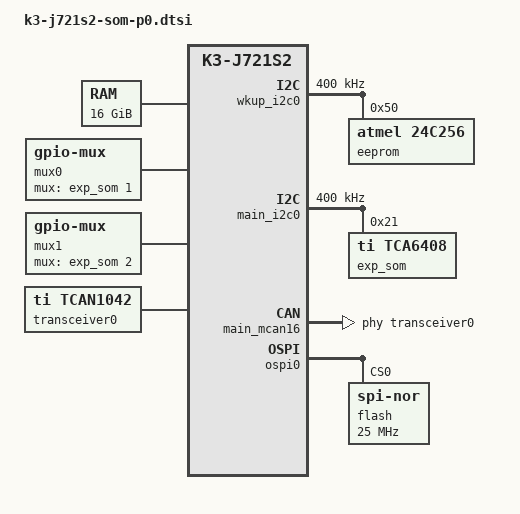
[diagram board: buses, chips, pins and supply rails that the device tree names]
/dts-v1/;
#include "k3-j721s2.dtsi"
#include <dt-bindings/gpio/gpio.h>
/ {
	memory@80000000 {
		device_type = "memory";
		reg = <0x00 0x80000000 0x00 0x80000000>,
		      <0x08 0x80000000 0x03 0x80000000>;
	};
	reserved_memory: reserved-memory {
		#address-cells = <2>;
		#size-cells = <2>;
		ranges;
		secure_ddr: optee@9e800000 {
			reg = <0x00 0x9e800000 0x00 0x01800000>;
			alignment = <0x1000>;
			no-map;
		};
	};
	mux0: mux-controller {
		compatible = "gpio-mux";
		#mux-state-cells = <1>;
		mux-gpios = <&exp_som 1 GPIO_ACTIVE_HIGH>;
	};
	mux1: mux-controller {
		compatible = "gpio-mux";
		#mux-state-cells = <1>;
		mux-gpios = <&exp_som 2 GPIO_ACTIVE_HIGH>;
	};
	transceiver0: can-phy0 {
		compatible = "ti,tcan1042";
		#phy-cells = <0>;
		max-bitrate = <5000000>;
	};
};
&wkup_pmx0 {
	mcu_fss0_ospi0_pins_default: mcu-fss0-ospi0-default-pins {
		pinctrl-single,pins = <
			J721S2_WKUP_IOPAD(0x000, PIN_OUTPUT, 0)  
			J721S2_WKUP_IOPAD(0x02c, PIN_OUTPUT, 0)  
			J721S2_WKUP_IOPAD(0x00c, PIN_INPUT, 0)  
			J721S2_WKUP_IOPAD(0x010, PIN_INPUT, 0)  
			J721S2_WKUP_IOPAD(0x014, PIN_INPUT, 0)  
			J721S2_WKUP_IOPAD(0x018, PIN_INPUT, 0)  
			J721S2_WKUP_IOPAD(0x01c, PIN_INPUT, 0)  
			J721S2_WKUP_IOPAD(0x020, PIN_INPUT, 0)  
			J721S2_WKUP_IOPAD(0x024, PIN_INPUT, 0)  
			J721S2_WKUP_IOPAD(0x028, PIN_INPUT, 0)  
			J721S2_WKUP_IOPAD(0x008, PIN_INPUT, 0)  
			J721S2_WKUP_IOPAD(0x004, PIN_INPUT, 0)  
		>;
	};
};
&wkup_pmx2 {
	wkup_i2c0_pins_default: wkup-i2c0-default-pins {
		pinctrl-single,pins = <
			J721S2_WKUP_IOPAD(0x98, PIN_INPUT, 0)  
			J721S2_WKUP_IOPAD(0x9c, PIN_INPUT, 0)  
		>;
	};
};
&main_pmx0 {
	main_i2c0_pins_default: main-i2c0-default-pins {
		pinctrl-single,pins = <
			J721S2_IOPAD(0x0e0, PIN_INPUT_PULLUP, 0)  
			J721S2_IOPAD(0x0e4, PIN_INPUT_PULLUP, 0)  
		>;
	};
	main_mcan16_pins_default: main-mcan16-default-pins {
		pinctrl-single,pins = <
			J721S2_IOPAD(0x028, PIN_INPUT, 0)  
			J721S2_IOPAD(0x024, PIN_OUTPUT, 0)  
		>;
	};
};
&wkup_i2c0 {
	status = "okay";
	pinctrl-names = "default";
	pinctrl-0 = <&wkup_i2c0_pins_default>;
	clock-frequency = <400000>;
	eeprom@50 {
		compatible = "atmel,24c256";
		reg = <0x50>;
	};
};
&main_i2c0 {
	status = "okay";
	pinctrl-names = "default";
	pinctrl-0 = <&main_i2c0_pins_default>;
	clock-frequency = <400000>;
	exp_som: gpio@21 {
		compatible = "ti,tca6408";
		reg = <0x21>;
		gpio-controller;
		#gpio-cells = <2>;
		gpio-line-names = "USB2.0_MUX_SEL", "CANUART_MUX1_SEL0",
				  "CANUART_MUX2_SEL0", "CANUART_MUX_SEL1",
				  "GPIO_RGMII1_RST", "GPIO_eDP_ENABLE",
				   "GPIO_LIN_EN", "CAN_STB";
	};
};
&main_mcan16 {
	status = "okay";
	pinctrl-0 = <&main_mcan16_pins_default>;
	pinctrl-names = "default";
	phys = <&transceiver0>;
};
&ospi0 {
	status = "okay";
	pinctrl-names = "default";
	pinctrl-0 = <&mcu_fss0_ospi0_pins_default>;
	flash@0 {
		compatible = "jedec,spi-nor";
		reg = <0x0>;
		spi-tx-bus-width = <8>;
		spi-rx-bus-width = <8>;
		spi-max-frequency = <25000000>;
		cdns,tshsl-ns = <60>;
		cdns,tsd2d-ns = <60>;
		cdns,tchsh-ns = <60>;
		cdns,tslch-ns = <60>;
		cdns,read-delay = <4>;
	};
};
